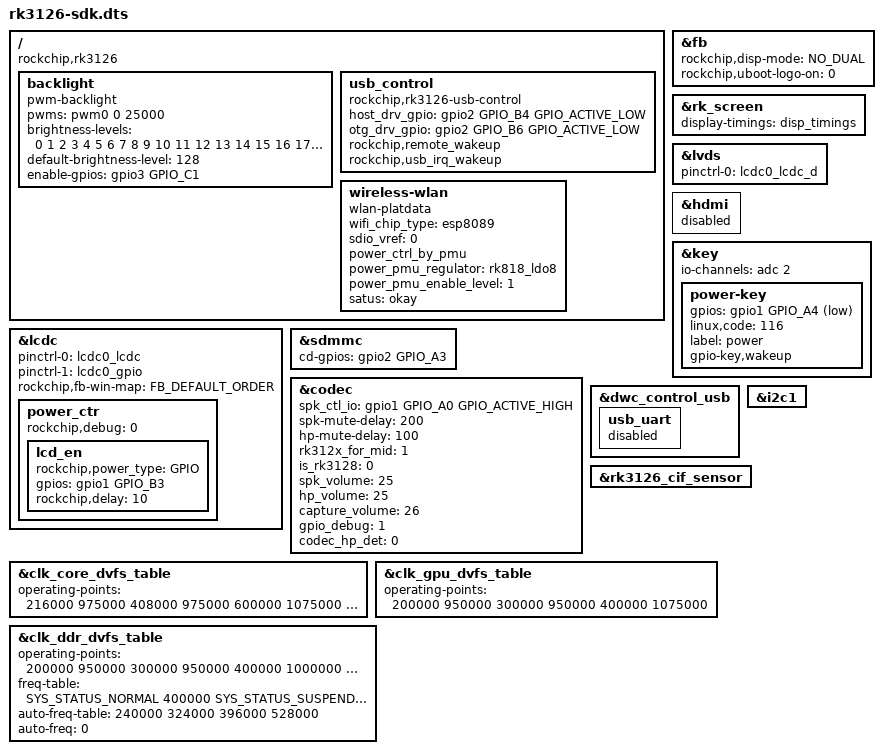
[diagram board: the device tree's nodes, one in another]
#include "rk312x-sdk.dtsi"
#include "lcd-b101ew05.dtsi"

/ {
	 compatible = "rockchip,rk3126";
        backlight {
                compatible = "pwm-backlight";
                pwms = <&pwm0 0 25000>;
                brightness-levels = <0 1 2 3 4 5 6 7 8 9 10 11 12 13 14 15 16 17 18 19 20 21 22 23 24 25 26 27 28 29 30 31 32 33 34 35 36 37 38 39 40 41 42 43 44 45 46 47 48 49 50 51 52 53 54 55 56 57 58 59 60 61 62 63 64 65 66 67 68 69 70 71 72 73 74 75 76 77 78 79 80 81 82 83 84 85 86 87 88 89 90 91 92 93 94 95 96 97 98 99 100 101 102 103 104 105 106 107 108 109 110 111 112 113 114 115 116 117 118 119 120 121 122 123 124 125 126 127 128 129 130 131 132 133 134 135 136 137 138 139 140 141 142 143 144 145 146 147 148 149 150 151 152 153 154 155 156 157 158 159 160 161 162 163 164 165 166 167 168 169 170 171 172 173 174 175 176 177 178 179 180 181 182 183 184 185 186 187 188 189 190 191 192 193 194 195 196 197 198 199 200 201 202 203 204 205 206 207 208 209 210 211 212 213 214 215 216 217 218 219 220 221 222 223 224 225 226 227 228 229 230 231 232 233 234 235 236 237 238 239 240 241 242 243 244 245 246 247 248 249 250 251 252 253 254 255>;
                default-brightness-level = <128>;
                enable-gpios = <&gpio3 GPIO_C1 GPIO_ACTIVE_HIGH>;
        };

	usb_control {
		compatible = "rockchip,rk3126-usb-control";
		host_drv_gpio = <&gpio2 GPIO_B4 GPIO_ACTIVE_LOW>;
		otg_drv_gpio = <&gpio2 GPIO_B6 GPIO_ACTIVE_LOW>;

		rockchip,remote_wakeup;
		rockchip,usb_irq_wakeup;
		};
        
        wireless-wlan {		
	       compatible = "wlan-platdata";
	       wifi_chip_type = "esp8089";
	       sdio_vref = <0>; //1800mv or 3300mv
	       
	       power_ctrl_by_pmu;
	       power_pmu_regulator = "rk818_ldo8";
	       power_pmu_enable_level = <1>; //1->HIGH, 0->LOW
	       
	       //vref_ctrl_enable;
	       //vref_pmu_regulator = "rk818_ldo8";
	       //vref_pmu_enable_level = <1>; //1->HIGH, 0->LOW
	       
	       satus = "okay";	
	 };	
};

&fb {
        rockchip,disp-mode = <NO_DUAL>;
	rockchip,uboot-logo-on = <0>;
};

&rk_screen {
	display-timings = <&disp_timings>;
};

&lvds {
	status = "okay";

	pinctrl-names = "lcdc";
	pinctrl-0 = <&lcdc0_lcdc_d>;
};

&lcdc {
	status = "okay";

	pinctrl-names = "default", "gpio";
	pinctrl-0 = <&lcdc0_lcdc>;
	pinctrl-1 = <&lcdc0_gpio>;

	rockchip,fb-win-map = <FB_DEFAULT_ORDER>;

	power_ctr: power_ctr {
		rockchip,debug = <0>;
		lcd_en: lcd_en {
			rockchip,power_type = <GPIO>;
			gpios = <&gpio1 GPIO_B3 GPIO_ACTIVE_HIGH>;
			rockchip,delay = <10>;
		};
	};
};

&hdmi {
        status = "disabled";
};

&key {
		io-channels = <&adc 2>;
		power-key {
			gpios = <&gpio1 GPIO_A4 GPIO_ACTIVE_LOW>;
			linux,code = <116>;
			label = "power";
			gpio-key,wakeup;
		};
};
&sdmmc {
	cd-gpios = <&gpio2 GPIO_A3 GPIO_ACTIVE_HIGH>;/*CD GPIO*/
};

&codec {
	spk_ctl_io = <&gpio1 GPIO_A0 GPIO_ACTIVE_HIGH>;
	spk-mute-delay = <200>;
	hp-mute-delay = <100>;
	rk312x_for_mid = <1>;
	is_rk3128 = <0>;
	spk_volume = <25>;
	hp_volume = <25>;
	capture_volume = <26>;
	gpio_debug = <1>;
	codec_hp_det = <0>;

};

&dwc_control_usb {
	usb_uart {
		status = "disabled";
	};
};

&i2c1 {
	status = "okay";
};

&rk3126_cif_sensor{
	status = "okay";
};

&clk_core_dvfs_table {
	operating-points = <
		/* KHz    uV */
		216000 975000
		408000 975000
		600000 1075000
		696000 1100000
		816000 1150000
		1008000 1300000
		1200000 1375000
		>;
	status="okay";
};

&clk_gpu_dvfs_table {
	operating-points = <
		/* KHz    uV */
		200000 950000
		300000 950000
		400000 1075000
		//480000 1175000
		>;
	status="okay";
};

&clk_ddr_dvfs_table {
	operating-points = <
		/* KHz    uV */
		200000 950000
		300000 950000
		400000 1000000
		533000 1225000
		>;

	freq-table = <
		/*status		freq(KHz)*/
		SYS_STATUS_NORMAL	400000
		SYS_STATUS_SUSPEND	200000
		SYS_STATUS_VIDEO_1080P  240000
		SYS_STATUS_VIDEO_4K     400000
		SYS_STATUS_PERFORMANCE  528000
		SYS_STATUS_DUALVIEW	400000
		SYS_STATUS_BOOST	324000
		SYS_STATUS_ISP		533000
		>;
	auto-freq-table = <
		240000
		324000
		396000
		528000
		>;
	auto-freq=<0>;
	status="okay";
};
